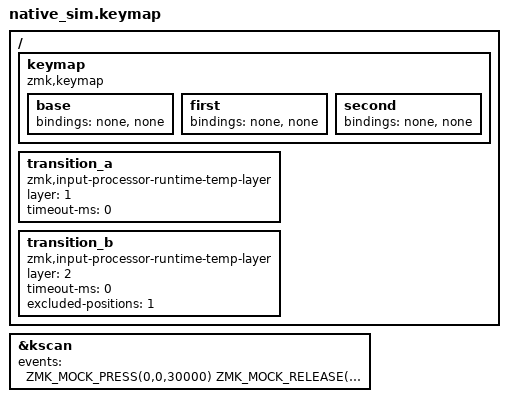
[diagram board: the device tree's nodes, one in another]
/* Copyright (c) 2026 amgskobo; SPDX-License-Identifier: MIT */
#include <behaviors.dtsi>
#include <dt-bindings/zmk/kscan_mock.h>
/ {
    keymap {
        compatible = "zmk,keymap";
        base { bindings = <&none &none>; };
        first { bindings = <&none &none>; };
        second { bindings = <&none &none>; };
    };
    transition_a: transition_a {
        compatible = "zmk,input-processor-runtime-temp-layer";
        #input-processor-cells = <0>;
        layer = <1>;
        timeout-ms = <0>;
    };
    transition_b: transition_b {
        compatible = "zmk,input-processor-runtime-temp-layer";
        #input-processor-cells = <0>;
        layer = <2>;
        timeout-ms = <0>;
        excluded-positions = <1>;
    };
};
&kscan { events = <ZMK_MOCK_PRESS(0,0,30000) ZMK_MOCK_RELEASE(0,0,10)>; };
